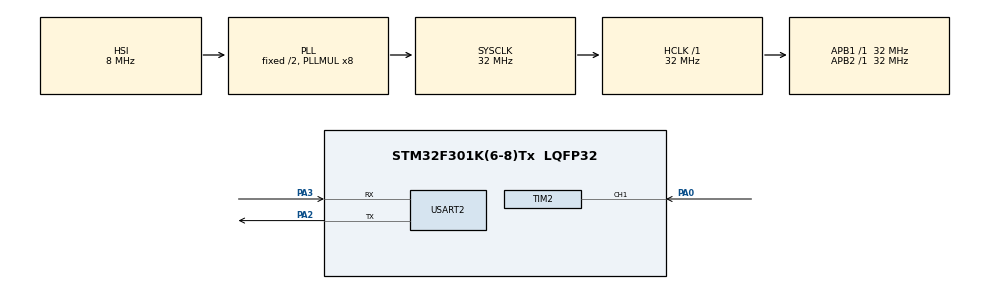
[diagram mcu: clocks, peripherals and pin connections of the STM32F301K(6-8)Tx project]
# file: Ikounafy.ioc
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Mcu.Family=STM32F3
Mcu.Name=STM32F301K(6-8)Tx
Mcu.Package=LQFP32
NVIC.PriorityGroup=NVIC_PRIORITYGROUP_4
NVIC.TIM2_IRQn=true\:0\:0\:false\:false\:true\:true\:true\:true
PA0.Signal=S_TIM2_CH1_ETR
PA2.Mode=Asynchronous
PA2.Signal=USART2_TX
PA3.Mode=Asynchronous
PA3.Signal=USART2_RX
ProjectManager.HeapSize=0x200
ProjectManager.StackSize=0x400
ProjectManager.TargetToolchain=STM32CubeIDE
RCC.AHBFreq_Value=32000000
RCC.APB1Freq_Value=32000000
RCC.APB1TimFreq_Value=32000000
RCC.APB2Freq_Value=32000000
RCC.APB2TimFreq_Value=32000000
RCC.CortexFreq_Value=32000000
RCC.HCLKFreq_Value=32000000
RCC.HSE_VALUE=8000000
RCC.HSI_VALUE=8000000
RCC.PLLMUL=RCC_PLL_MUL8
RCC.SYSCLKFreq_VALUE=32000000
RCC.SYSCLKSourceVirtual=RCC_SYSCLKSOURCE_PLLCLK
SH.S_TIM2_CH1_ETR.0=TIM2_CH1,Input_Capture1_from_TI1
TIM2.Channel-Input_Capture1_from_TI1=TIM_CHANNEL_1
USART2.VirtualMode-Asynchronous=VM_ASYNC
VP_TIM2_VS_ClockSourceINT.Mode=Internal
board=custom

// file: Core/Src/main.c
/* USER CODE BEGIN Header */
/**
  ******************************************************************************
  * @file           : main.c
  * @brief          : Main program body
  ******************************************************************************
  * @attention
  *
  * Copyright (c) 2026 STMicroelectronics.
  * All rights reserved.
  *
  * This software is licensed under terms that can be found in the LICENSE file
  * in the root directory of this software component.
  * If no LICENSE file comes with this software, it is provided AS-IS.
  *
  ******************************************************************************
  */
/* USER CODE END Header */
#include "main.h"
#include <stdio.h>
#include <string.h>

/* USER CODE BEGIN PD */
#define BIN_EMPTY_FREQ_HZ   65500  // Calibrated oscillator frequency when the bin is empty
#define BIN_FULL_FREQ_HZ    43900  // Calibrated oscillator frequency when the bin is full
#define NUM_SAMPLES         30     // Number of measurements averaged per reading
/* USER CODE END PD */

TIM_HandleTypeDef htim2;

UART_HandleTypeDef huart2;

void SystemClock_Config(void);
static void MX_GPIO_Init(void);
static void MX_TIM2_Init(void);
static void MX_USART2_UART_Init(void);

/* USER CODE BEGIN 0 */

volatile int is_first_capture = 0;
volatile int ic_value_1 = 0;
volatile int ic_value_2 = 0;
volatile int capture_difference = 0;
volatile int measured_frequency = 0;
volatile int calculation_ready = 0;
char uart_tx_buffer[50];
int measurements[NUM_SAMPLES];
int measurement_index = 0;

/* USER CODE END 0 */

int main(void)
{

  /* MCU Configuration--------------------------------------------------------*/

  /* Reset of all peripherals, Initializes the Flash interface and the Systick. */
  HAL_Init();

  /* Configure the system clock */
  SystemClock_Config();

  /* Initialize all configured peripherals */
  MX_GPIO_Init();
  MX_TIM2_Init();
  MX_USART2_UART_Init();
  /* USER CODE BEGIN 2 */
  HAL_TIM_IC_Start_IT(&htim2, TIM_CHANNEL_1);
  /* USER CODE END 2 */

  /* Infinite loop */
  /* USER CODE BEGIN WHILE */

  while (1)
  {
      if (calculation_ready == 1)
      {
          measurements[measurement_index] = measured_frequency;
          measurement_index++;

          if (measurement_index >= NUM_SAMPLES)
          {
              int sum = 0;
              for (int i = 0; i < NUM_SAMPLES; i++)
                  sum += measurements[i];
              int average = sum / NUM_SAMPLES;

              int fill_level_percent;
              if (average >= BIN_EMPTY_FREQ_HZ)
                  fill_level_percent = 0;
              else if (average <= BIN_FULL_FREQ_HZ)
                  fill_level_percent = 100;
              else
                  fill_level_percent = (int)(100.0f *
                      (BIN_EMPTY_FREQ_HZ - average) /
                      (BIN_EMPTY_FREQ_HZ - BIN_FULL_FREQ_HZ));

              sprintf(uart_tx_buffer, "LEVEL:%d\r\n", fill_level_percent);
              HAL_UART_Transmit(&huart2,
                  (uint8_t*)uart_tx_buffer,
                  strlen(uart_tx_buffer), 200);
              measurement_index = 0;
          }
          calculation_ready = 0;
      }
      HAL_Delay(100);
  }
}

void SystemClock_Config(void)
{
  RCC_OscInitTypeDef RCC_OscInitStruct = {0};
  RCC_ClkInitTypeDef RCC_ClkInitStruct = {0};

  /** Initializes the RCC Oscillators according to the specified parameters
  * in the RCC_OscInitTypeDef structure.
  */
  RCC_OscInitStruct.OscillatorType = RCC_OSCILLATORTYPE_HSI;
  RCC_OscInitStruct.HSIState = RCC_HSI_ON;
  RCC_OscInitStruct.HSICalibrationValue = RCC_HSICALIBRATION_DEFAULT;
  RCC_OscInitStruct.PLL.PLLState = RCC_PLL_ON;
  RCC_OscInitStruct.PLL.PLLSource = RCC_PLLSOURCE_HSI;
  RCC_OscInitStruct.PLL.PLLMUL = RCC_PLL_MUL8;
  if (HAL_RCC_OscConfig(&RCC_OscInitStruct) != HAL_OK)
  {
    Error_Handler();
  }

  /** Initializes the CPU, AHB and APB buses clocks
  */
  RCC_ClkInitStruct.ClockType = RCC_CLOCKTYPE_HCLK|RCC_CLOCKTYPE_SYSCLK
                              |RCC_CLOCKTYPE_PCLK1|RCC_CLOCKTYPE_PCLK2;
  RCC_ClkInitStruct.SYSCLKSource = RCC_SYSCLKSOURCE_PLLCLK;
  RCC_ClkInitStruct.AHBCLKDivider = RCC_SYSCLK_DIV1;
  RCC_ClkInitStruct.APB1CLKDivider = RCC_HCLK_DIV1;
  RCC_ClkInitStruct.APB2CLKDivider = RCC_HCLK_DIV1;

  if (HAL_RCC_ClockConfig(&RCC_ClkInitStruct, FLASH_LATENCY_1) != HAL_OK)
  {
    Error_Handler();
  }
}

static void MX_TIM2_Init(void)
{

  TIM_ClockConfigTypeDef sClockSourceConfig = {0};
  TIM_MasterConfigTypeDef sMasterConfig = {0};
  TIM_IC_InitTypeDef sConfigIC = {0};

  htim2.Instance = TIM2;
  htim2.Init.Prescaler = 0;
  htim2.Init.CounterMode = TIM_COUNTERMODE_UP;
  htim2.Init.Period = 4294967295;
  htim2.Init.ClockDivision = TIM_CLOCKDIVISION_DIV1;
  htim2.Init.AutoReloadPreload = TIM_AUTORELOAD_PRELOAD_DISABLE;
  if (HAL_TIM_Base_Init(&htim2) != HAL_OK)
  {
    Error_Handler();
  }
  sClockSourceConfig.ClockSource = TIM_CLOCKSOURCE_INTERNAL;
  if (HAL_TIM_ConfigClockSource(&htim2, &sClockSourceConfig) != HAL_OK)
  {
    Error_Handler();
  }
  if (HAL_TIM_IC_Init(&htim2) != HAL_OK)
  {
    Error_Handler();
  }
  sMasterConfig.MasterOutputTrigger = TIM_TRGO_RESET;
  sMasterConfig.MasterSlaveMode = TIM_MASTERSLAVEMODE_DISABLE;
  if (HAL_TIMEx_MasterConfigSynchronization(&htim2, &sMasterConfig) != HAL_OK)
  {
    Error_Handler();
  }
  sConfigIC.ICPolarity = TIM_INPUTCHANNELPOLARITY_RISING;
  sConfigIC.ICSelection = TIM_ICSELECTION_DIRECTTI;
  sConfigIC.ICPrescaler = TIM_ICPSC_DIV1;
  sConfigIC.ICFilter = 0;
  if (HAL_TIM_IC_ConfigChannel(&htim2, &sConfigIC, TIM_CHANNEL_1) != HAL_OK)
  {
    Error_Handler();
  }

}

static void MX_USART2_UART_Init(void)
{

  huart2.Instance = USART2;
  huart2.Init.BaudRate = 38400;
  huart2.Init.WordLength = UART_WORDLENGTH_8B;
  huart2.Init.StopBits = UART_STOPBITS_1;
  huart2.Init.Parity = UART_PARITY_NONE;
  huart2.Init.Mode = UART_MODE_TX_RX;
  huart2.Init.HwFlowCtl = UART_HWCONTROL_NONE;
  huart2.Init.OverSampling = UART_OVERSAMPLING_16;
  huart2.Init.OneBitSampling = UART_ONE_BIT_SAMPLE_DISABLE;
  huart2.AdvancedInit.AdvFeatureInit = UART_ADVFEATURE_NO_INIT;
  if (HAL_UART_Init(&huart2) != HAL_OK)
  {
    Error_Handler();
  }

}

static void MX_GPIO_Init(void)
{

  /* GPIO Ports Clock Enable */
  __HAL_RCC_GPIOA_CLK_ENABLE();

}

/* USER CODE BEGIN 4 */

void HAL_TIM_IC_CaptureCallback(TIM_HandleTypeDef *htim2)
{

	if (htim2->Channel == HAL_TIM_ACTIVE_CHANNEL_1)
	{
		if (is_first_capture == 0)
			{
				ic_value_1 = HAL_TIM_ReadCapturedValue(htim2, TIM_CHANNEL_1);
				is_first_capture = 1;
			}
		else if (is_first_capture)
		{
			ic_value_2 = HAL_TIM_ReadCapturedValue(htim2, TIM_CHANNEL_1);
			if (ic_value_2 > ic_value_1)
						{
				capture_difference = ic_value_2 - ic_value_1;
				measured_frequency = (float)HAL_RCC_GetHCLKFreq()/(float)capture_difference;

				calculation_ready = 1;
						}
			else calculation_ready = 0;
			is_first_capture = 0;
		}
	}
}
/* USER CODE END 4 */

void Error_Handler(void)
{
  __disable_irq();
  while (1)
  {
  }
}
